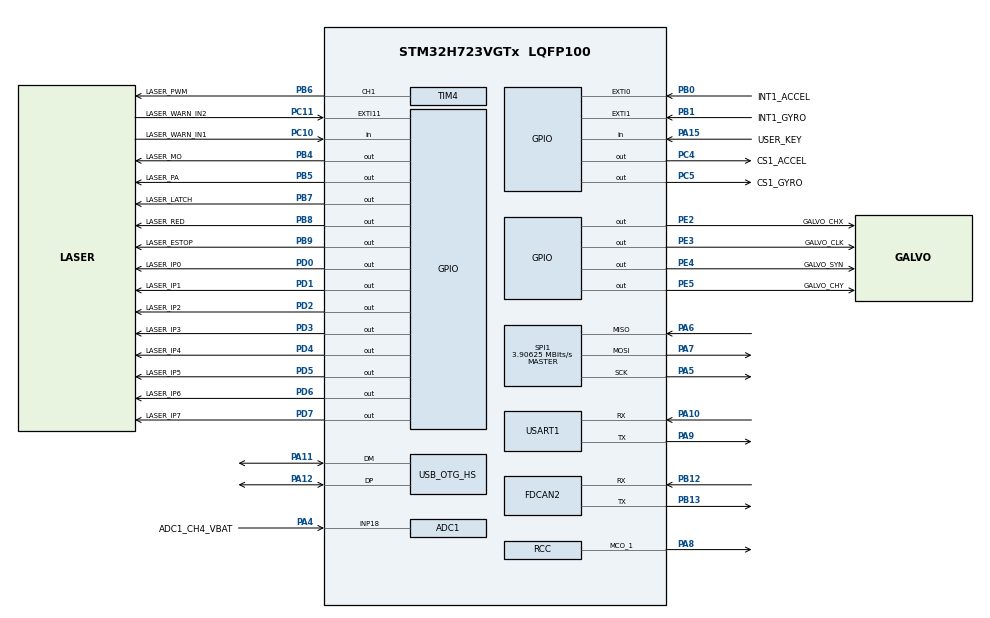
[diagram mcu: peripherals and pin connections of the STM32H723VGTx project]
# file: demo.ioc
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ADC1.Channel-0\#ChannelRegularConversion=ADC_CHANNEL_18
ADC1.ClockPrescaler=ADC_CLOCK_ASYNC_DIV64
ADC1.NbrOfConversionFlag=1
ADC1.OffsetNumber-0\#ChannelRegularConversion=ADC_OFFSET_NONE
ADC1.OffsetSignedSaturation-0\#ChannelRegularConversion=DISABLE
ADC1.Rank-0\#ChannelRegularConversion=1
ADC1.SamplingTime-0\#ChannelRegularConversion=ADC_SAMPLETIME_1CYCLE_5
ADC1.master=1
CORTEX_M7.AccessPermission_Spec=MPU_REGION_FULL_ACCESS
CORTEX_M7.BaseAddress_Spec=0x30000000
CORTEX_M7.CPU_DCache=Enabled
CORTEX_M7.CPU_ICache=Enabled
CORTEX_M7.Enable_S-Cortex_Memory_Protection_Unit_Region1_Settings_S=__NULL
CORTEX_M7.IsShareable_Spec=MPU_ACCESS_NOT_SHAREABLE
CORTEX_M7.MPU_Control=MPU_PRIVILEGED_DEFAULT
CORTEX_M7.Size_Spec=MPU_REGION_SIZE_16KB
CORTEX_M7.SubRegionDisable_Spec=0x0
CORTEX_M7.TypeExtField_Spec=MPU_TEX_LEVEL1
CORTEX_M7.default_mode_Activation=1
Dma.Request0=SPI1_RX
Dma.Request1=SPI1_TX
Dma.Request2=USART1_RX
Dma.Request3=USART1_TX
Dma.Request4=TIM7_UP
Dma.SPI1_RX.0.Direction=DMA_PERIPH_TO_MEMORY
Dma.SPI1_RX.0.EventEnable=DISABLE
Dma.SPI1_RX.0.FIFOMode=DMA_FIFOMODE_DISABLE
Dma.SPI1_RX.0.Instance=DMA1_Stream0
Dma.SPI1_RX.0.MemDataAlignment=DMA_MDATAALIGN_BYTE
Dma.SPI1_RX.0.MemInc=DMA_MINC_ENABLE
Dma.SPI1_RX.0.Mode=DMA_NORMAL
Dma.SPI1_RX.0.PeriphDataAlignment=DMA_PDATAALIGN_BYTE
Dma.SPI1_RX.0.PeriphInc=DMA_PINC_DISABLE
Dma.SPI1_RX.0.Polarity=HAL_DMAMUX_REQ_GEN_RISING
Dma.SPI1_RX.0.Priority=DMA_PRIORITY_VERY_HIGH
Dma.SPI1_RX.0.RequestNumber=1
Dma.SPI1_RX.0.SignalID=NONE
Dma.SPI1_RX.0.SyncEnable=DISABLE
Dma.SPI1_RX.0.SyncPolarity=HAL_DMAMUX_SYNC_NO_EVENT
Dma.SPI1_RX.0.SyncRequestNumber=1
Dma.SPI1_RX.0.SyncSignalID=NONE
Dma.SPI1_TX.1.Direction=DMA_MEMORY_TO_PERIPH
Dma.SPI1_TX.1.EventEnable=DISABLE
Dma.SPI1_TX.1.FIFOMode=DMA_FIFOMODE_DISABLE
Dma.SPI1_TX.1.Instance=DMA1_Stream1
Dma.SPI1_TX.1.MemDataAlignment=DMA_MDATAALIGN_BYTE
Dma.SPI1_TX.1.MemInc=DMA_MINC_ENABLE
Dma.SPI1_TX.1.Mode=DMA_NORMAL
Dma.SPI1_TX.1.PeriphDataAlignment=DMA_PDATAALIGN_BYTE
Dma.SPI1_TX.1.PeriphInc=DMA_PINC_DISABLE
Dma.SPI1_TX.1.Polarity=HAL_DMAMUX_REQ_GEN_RISING
Dma.SPI1_TX.1.Priority=DMA_PRIORITY_VERY_HIGH
Dma.SPI1_TX.1.RequestNumber=1
Dma.SPI1_TX.1.SignalID=NONE
Dma.SPI1_TX.1.SyncEnable=DISABLE
Dma.SPI1_TX.1.SyncPolarity=HAL_DMAMUX_SYNC_NO_EVENT
Dma.SPI1_TX.1.SyncRequestNumber=1
Dma.SPI1_TX.1.SyncSignalID=NONE
Dma.TIM7_UP.4.Direction=DMA_MEMORY_TO_PERIPH
Dma.TIM7_UP.4.EventEnable=DISABLE
Dma.TIM7_UP.4.FIFOMode=DMA_FIFOMODE_DISABLE
Dma.TIM7_UP.4.Instance=DMA1_Stream4
Dma.TIM7_UP.4.MemDataAlignment=DMA_MDATAALIGN_WORD
Dma.TIM7_UP.4.MemInc=DMA_MINC_ENABLE
Dma.TIM7_UP.4.Mode=DMA_NORMAL
Dma.TIM7_UP.4.PeriphDataAlignment=DMA_PDATAALIGN_WORD
Dma.TIM7_UP.4.PeriphInc=DMA_PINC_DISABLE
Dma.TIM7_UP.4.Polarity=HAL_DMAMUX_REQ_GEN_RISING
Dma.TIM7_UP.4.Priority=DMA_PRIORITY_VERY_HIGH
Dma.TIM7_UP.4.RequestNumber=1
Dma.TIM7_UP.4.SignalID=NONE
Dma.TIM7_UP.4.SyncEnable=DISABLE
Dma.TIM7_UP.4.SyncPolarity=HAL_DMAMUX_SYNC_NO_EVENT
Dma.TIM7_UP.4.SyncRequestNumber=1
Dma.TIM7_UP.4.SyncSignalID=NONE
Dma.USART1_RX.2.Direction=DMA_PERIPH_TO_MEMORY
Dma.USART1_RX.2.EventEnable=DISABLE
Dma.USART1_RX.2.FIFOMode=DMA_FIFOMODE_DISABLE
Dma.USART1_RX.2.Instance=DMA1_Stream2
Dma.USART1_RX.2.MemDataAlignment=DMA_MDATAALIGN_BYTE
Dma.USART1_RX.2.MemInc=DMA_MINC_ENABLE
Dma.USART1_RX.2.Mode=DMA_NORMAL
Dma.USART1_RX.2.PeriphDataAlignment=DMA_PDATAALIGN_BYTE
Dma.USART1_RX.2.PeriphInc=DMA_PINC_DISABLE
Dma.USART1_RX.2.Polarity=HAL_DMAMUX_REQ_GEN_RISING
Dma.USART1_RX.2.Priority=DMA_PRIORITY_LOW
Dma.USART1_RX.2.RequestNumber=1
Dma.USART1_RX.2.SignalID=NONE
Dma.USART1_RX.2.SyncEnable=DISABLE
Dma.USART1_RX.2.SyncPolarity=HAL_DMAMUX_SYNC_NO_EVENT
Dma.USART1_RX.2.SyncRequestNumber=1
Dma.USART1_RX.2.SyncSignalID=NONE
Dma.USART1_TX.3.Direction=DMA_MEMORY_TO_PERIPH
Dma.USART1_TX.3.EventEnable=DISABLE
Dma.USART1_TX.3.FIFOMode=DMA_FIFOMODE_DISABLE
Dma.USART1_TX.3.Instance=DMA1_Stream3
Dma.USART1_TX.3.MemDataAlignment=DMA_MDATAALIGN_BYTE
Dma.USART1_TX.3.MemInc=DMA_MINC_ENABLE
Dma.USART1_TX.3.Mode=DMA_NORMAL
Dma.USART1_TX.3.PeriphDataAlignment=DMA_PDATAALIGN_BYTE
Dma.USART1_TX.3.PeriphInc=DMA_PINC_DISABLE
Dma.USART1_TX.3.Polarity=HAL_DMAMUX_REQ_GEN_RISING
Dma.USART1_TX.3.Priority=DMA_PRIORITY_LOW
Dma.USART1_TX.3.RequestNumber=1
Dma.USART1_TX.3.SignalID=NONE
Dma.USART1_TX.3.SyncEnable=DISABLE
Dma.USART1_TX.3.SyncPolarity=HAL_DMAMUX_SYNC_NO_EVENT
Dma.USART1_TX.3.SyncRequestNumber=1
Dma.USART1_TX.3.SyncSignalID=NONE
FDCAN2.AutoRetransmission=ENABLE
FDCAN2.CalculateBaudRateNominal=1000000
FDCAN2.CalculateTimeBitNominal=1000
FDCAN2.CalculateTimeQuantumNominal=40.0
FDCAN2.DataPrescaler=3
FDCAN2.DataSyncJumpWidth=10
FDCAN2.DataTimeSeg1=29
FDCAN2.DataTimeSeg2=10
FDCAN2.NominalPrescaler=5
FDCAN2.NominalTimeSeg1=19
FDCAN2.NominalTimeSeg2=5
FDCAN2.RxFifo0ElmtsNbr=4
FDCAN2.RxFifo1ElmtsNbr=4
FDCAN2.StdFiltersNbr=14
FDCAN2.TxFifoQueueElmtsNbr=32
FREERTOS.Tasks01=defaultTask,24,3584,StartDefaultTask,Default,NULL,Dynamic,NULL,NULL
FREERTOS.configENABLE_FPU=1
FREERTOS.configTOTAL_HEAP_SIZE=25600
FREERTOS.configUSE_TIMERS=1
Mcu.Family=STM32H7
Mcu.Name=STM32H723VGTx
Mcu.Package=LQFP100
NVIC.DMA1_Stream0_IRQn=true\:5\:0\:false\:false\:true\:true\:false\:true\:true
NVIC.DMA1_Stream1_IRQn=true\:5\:0\:false\:false\:true\:true\:false\:true\:true
NVIC.DMA1_Stream2_IRQn=true\:5\:0\:false\:false\:true\:true\:false\:true\:true
NVIC.DMA1_Stream3_IRQn=true\:5\:0\:false\:false\:true\:true\:false\:true\:true
NVIC.DMA1_Stream4_IRQn=true\:5\:0\:false\:false\:true\:true\:false\:true\:true
NVIC.FDCAN2_IT0_IRQn=true\:5\:0\:false\:false\:true\:true\:true\:true\:true
NVIC.FDCAN2_IT1_IRQn=true\:5\:0\:false\:false\:true\:true\:true\:true\:true
NVIC.OTG_HS_IRQn=true\:5\:0\:false\:false\:true\:true\:true\:true\:true
NVIC.PriorityGroup=NVIC_PRIORITYGROUP_4
NVIC.SPI1_IRQn=true\:5\:0\:false\:false\:true\:true\:false\:true\:true
NVIC.TIM6_DAC_IRQn=true\:15\:0\:false\:false\:true\:false\:false\:true\:true
NVIC.TimeBase=TIM6_DAC_IRQn
NVIC.TimeBaseIP=TIM6
NVIC.USART1_IRQn=true\:5\:0\:false\:false\:true\:true\:true\:true\:true
PA10.Mode=Asynchronous
PA10.Signal=USART1_RX
PA11.Mode=Device_Only_FS
PA11.Signal=USB_OTG_HS_DM
PA12.Mode=Device_Only_FS
PA12.Signal=USB_OTG_HS_DP
PA13(JTMS/SWDIO).Mode=Serial_Wire
PA13(JTMS/SWDIO).Signal=DEBUG_JTMS-SWDIO
PA14(JTCK/SWCLK).Mode=Serial_Wire
PA14(JTCK/SWCLK).Signal=DEBUG_JTCK-SWCLK
PA15(JTDI).GPIO_Label=USER_KEY
PA15(JTDI).Signal=GPIO_Input
PA4.GPIO_Label=ADC1_CH4_VBAT
PA4.Signal=ADCx_INP18
PA5.GPIO_Speed=GPIO_SPEED_FREQ_VERY_HIGH
PA5.Mode=Full_Duplex_Master
PA5.Signal=SPI1_SCK
PA6.GPIO_Speed=GPIO_SPEED_FREQ_VERY_HIGH
PA6.Mode=Full_Duplex_Master
PA6.Signal=SPI1_MISO
PA7.GPIO_Speed=GPIO_SPEED_FREQ_VERY_HIGH
PA7.Mode=Full_Duplex_Master
PA7.Signal=SPI1_MOSI
PA8.Mode=Clock-out-1
PA8.Signal=RCC_MCO_1
PA9.Mode=Asynchronous
PA9.Signal=USART1_TX
PB0.GPIO_Label=INT1_ACCEL
PB0.Signal=GPXTI0
PB1.GPIO_Label=INT1_GYRO
PB1.Signal=GPXTI1
PB12.Mode=FDCAN_Activate
PB12.Signal=FDCAN2_RX
PB13.Mode=FDCAN_Activate
PB13.Signal=FDCAN2_TX
PB4(NJTRST).GPIO_Label=LASER_MO
PB4(NJTRST).GPIO_Speed=GPIO_SPEED_FREQ_VERY_HIGH
PB4(NJTRST).PinState=GPIO_PIN_RESET
PB4(NJTRST).Signal=GPIO_Output
PB5.GPIO_Label=LASER_PA
PB5.GPIO_Speed=GPIO_SPEED_FREQ_VERY_HIGH
PB5.PinState=GPIO_PIN_RESET
PB5.Signal=GPIO_Output
PB6.GPIO_Label=LASER_PWM
PB6.Signal=S_TIM4_CH1
PB7.GPIO_Label=LASER_LATCH
PB7.GPIO_Speed=GPIO_SPEED_FREQ_VERY_HIGH
PB7.PinState=GPIO_PIN_RESET
PB7.Signal=GPIO_Output
PB8.GPIO_Label=LASER_RED
PB8.GPIO_Speed=GPIO_SPEED_FREQ_VERY_HIGH
PB8.PinState=GPIO_PIN_RESET
PB8.Signal=GPIO_Output
PB9.GPIO_Label=LASER_ESTOP
PB9.GPIO_Speed=GPIO_SPEED_FREQ_VERY_HIGH
PB9.PinState=GPIO_PIN_RESET
PB9.Signal=GPIO_Output
PC10.GPIO_Label=LASER_WARN_IN1
PC10.GPIO_PuPd=GPIO_PULLUP
PC10.Signal=GPIO_Input
PC11.GPIO_Label=LASER_WARN_IN2
PC11.GPIO_PuPd=GPIO_PULLUP
PC11.Signal=GPXTI11
PC4.GPIO_Label=CS1_ACCEL
PC4.GPIO_Speed=GPIO_SPEED_FREQ_VERY_HIGH
PC4.PinState=GPIO_PIN_SET
PC4.Signal=GPIO_Output
PC5.GPIO_Label=CS1_GYRO
PC5.GPIO_Speed=GPIO_SPEED_FREQ_VERY_HIGH
PC5.PinState=GPIO_PIN_SET
PC5.Signal=GPIO_Output
PD0.GPIO_Label=LASER_IP0
PD0.GPIO_Speed=GPIO_SPEED_FREQ_VERY_HIGH
PD0.PinState=GPIO_PIN_RESET
PD0.Signal=GPIO_Output
PD1.GPIO_Label=LASER_IP1
PD1.GPIO_Speed=GPIO_SPEED_FREQ_VERY_HIGH
PD1.PinState=GPIO_PIN_RESET
PD1.Signal=GPIO_Output
PD2.GPIO_Label=LASER_IP2
PD2.GPIO_Speed=GPIO_SPEED_FREQ_VERY_HIGH
PD2.PinState=GPIO_PIN_RESET
PD2.Signal=GPIO_Output
PD3.GPIO_Label=LASER_IP3
PD3.GPIO_Speed=GPIO_SPEED_FREQ_VERY_HIGH
PD3.PinState=GPIO_PIN_RESET
PD3.Signal=GPIO_Output
PD4.GPIO_Label=LASER_IP4
PD4.GPIO_Speed=GPIO_SPEED_FREQ_VERY_HIGH
PD4.PinState=GPIO_PIN_RESET
PD4.Signal=GPIO_Output
PD5.GPIO_Label=LASER_IP5
PD5.GPIO_Speed=GPIO_SPEED_FREQ_VERY_HIGH
PD5.PinState=GPIO_PIN_RESET
PD5.Signal=GPIO_Output
PD6.GPIO_Label=LASER_IP6
PD6.GPIO_Speed=GPIO_SPEED_FREQ_VERY_HIGH
PD6.PinState=GPIO_PIN_RESET
PD6.Signal=GPIO_Output
PD7.GPIO_Label=LASER_IP7
PD7.GPIO_Speed=GPIO_SPEED_FREQ_VERY_HIGH
PD7.PinState=GPIO_PIN_RESET
PD7.Signal=GPIO_Output
PE2.GPIO_Label=GALVO_CHX
PE2.GPIO_Speed=GPIO_SPEED_FREQ_VERY_HIGH
PE2.Signal=GPIO_Output
PE3.GPIO_Label=GALVO_CLK
PE3.GPIO_Speed=GPIO_SPEED_FREQ_VERY_HIGH
PE3.Signal=GPIO_Output
PE4.GPIO_Label=GALVO_SYN
PE4.GPIO_Speed=GPIO_SPEED_FREQ_VERY_HIGH
PE4.Signal=GPIO_Output
PE5.GPIO_Label=GALVO_CHY
PE5.GPIO_Speed=GPIO_SPEED_FREQ_VERY_HIGH
PE5.Signal=GPIO_Output
PH0-OSC_IN.Mode=HSE-External-Oscillator
PH0-OSC_IN.Signal=RCC_OSC_IN
PH1-OSC_OUT.Mode=HSE-External-Oscillator
PH1-OSC_OUT.Signal=RCC_OSC_OUT
ProjectManager.HeapSize=0x1000
ProjectManager.StackSize=0x1000
ProjectManager.TargetToolchain=Makefile
RCC.ADCFreq_Value=100000000
RCC.APB1Freq_Value=125000000
RCC.APB2Freq_Value=125000000
RCC.APB3Freq_Value=125000000
RCC.APB4Freq_Value=125000000
RCC.CortexFreq_Value=500000000
RCC.D1PPRE=RCC_APB3_DIV2
RCC.D2PPRE1=RCC_APB1_DIV2
RCC.D2PPRE2=RCC_APB2_DIV2
RCC.D3PPRE=RCC_APB4_DIV2
RCC.DIVM1=2
RCC.DIVM2=2
RCC.DIVM3=5
RCC.DIVN1=40
RCC.DIVN2=16
RCC.DIVN3=96
RCC.DIVP1=1
RCC.DIVP3=10
RCC.DIVQ1=4
RCC.HCLKFreq_Value=250000000
RCC.HPRE=RCC_HCLK_DIV2
RCC.PLL2FRACN=0
RCC.PLL3FRACN=0
RCC.PLLFRACN=0
RCC.PLLSourceVirtual=RCC_PLLSOURCE_HSE
RCC.SYSCLKFreq_VALUE=500000000
RCC.SYSCLKSource=RCC_SYSCLKSOURCE_PLLCLK
RCC.USBCLockSelection=RCC_USBCLKSOURCE_HSI48
RCC.USBFreq_Value=48000000
SH.ADCx_INP18.0=ADC1_INP18,IN18-Single-Ended
SH.S_TIM4_CH1.0=TIM4_CH1,PWM Generation1 CH1
SPI1.BaudRatePrescaler=SPI_BAUDRATEPRESCALER_32
SPI1.CLKPhase=SPI_PHASE_2EDGE
SPI1.CLKPolarity=SPI_POLARITY_HIGH
SPI1.CalculateBaudRate=3.90625 MBits/s
SPI1.DataSize=SPI_DATASIZE_8BIT
SPI1.Direction=SPI_DIRECTION_2LINES
SPI1.Mode=SPI_MODE_MASTER
SPI1.VirtualType=VM_MASTER
TIM4.Channel-PWM\ Generation1\ CH1=TIM_CHANNEL_1
TIM7.AutoReloadPreload=TIM_AUTORELOAD_PRELOAD_ENABLE
TIM7.Period=61
TIM7.TIM_MasterOutputTrigger=TIM_TRGO_UPDATE
USART1.VirtualMode-Asynchronous=VM_ASYNC
USB_DEVICE.CLASS_NAME_HS=CDC
USB_DEVICE.VirtualMode=Cdc
USB_DEVICE.VirtualModeHS=Cdc_HS
USB_OTG_HS.VirtualMode-Device_Only_FS=Device_Only_FS
VP_FREERTOS_VS_CMSIS_V2.Mode=CMSIS_V2
VP_MEMORYMAP_VS_MEMORYMAP.Mode=CurAppReg
VP_RCC_USB.Mode=USB_HS
VP_SYS_VS_tim6.Mode=TIM6
VP_TIM4_VS_ClockSourceINT.Mode=Internal
VP_TIM4_VS_OPM.Mode=OPM_bit
VP_TIM7_VS_ClockSourceINT.Mode=Enable_Timer
VP_USB_DEVICE_VS_USB_DEVICE_CDC_HS.Mode=CDC_HS
board=custom

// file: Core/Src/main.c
/* USER CODE BEGIN Header */
/**
  ******************************************************************************
  * @file           : main.c
  * @brief          : Main program body
  ******************************************************************************
  * @attention
  *
  * Copyright (c) 2026 STMicroelectronics.
  * All rights reserved.
  *
  * This software is licensed under terms that can be found in the LICENSE file
  * in the root directory of this software component.
  * If no LICENSE file comes with this software, it is provided AS-IS.
  *
  ******************************************************************************
  */
/* USER CODE END Header */
#include "main.h"
#include "cmsis_os.h"
#include "adc.h"
#include "dma.h"
#include "fdcan.h"
#include "spi.h"
#include "tim.h"
#include "usart.h"
#include "usb_device.h"
#include "gpio.h"

/* USER CODE BEGIN Includes */
#include "robot.h"
#include "bsp_log.h"
/* USER CODE END Includes */

void SystemClock_Config(void);
static void MPU_Config(void);
void MX_FREERTOS_Init(void);

int main(void)
{

  /* MPU Configuration--------------------------------------------------------*/
  MPU_Config();

  /* Enable the CPU Cache */

  /* Enable I-Cache---------------------------------------------------------*/
  SCB_EnableICache();

  /* Enable D-Cache---------------------------------------------------------*/
  SCB_EnableDCache();

  /* MCU Configuration--------------------------------------------------------*/

  /* Reset of all peripherals, Initializes the Flash interface and the Systick. */
  HAL_Init();

  /* Configure the system clock */
  SystemClock_Config();

  /* Initialize all configured peripherals */
  MX_GPIO_Init();
  MX_DMA_Init();
  MX_SPI1_Init();
  MX_USART1_UART_Init();
  MX_FDCAN2_Init();
  MX_TIM4_Init();
  MX_TIM7_Init();
  MX_ADC1_Init();
  /* USER CODE BEGIN 2 */
  RobotInit(); // 唯一的初始化入口（你的云台和激光逻辑都在这里面）
  LOGINFO("[main] SystemInit() and RobotInit() done");
  /* USER CODE END 2 */

  /* Init scheduler */
  osKernelInitialize();  /* Call init function for freertos objects (in cmsis_os2.c) */
  MX_FREERTOS_Init();

  /* Start scheduler */
  osKernelStart();

  /* We should never get here as control is now taken by the scheduler */

  /* Infinite loop */
  while (1)
  {

  }
}

void SystemClock_Config(void)
{
  RCC_OscInitTypeDef RCC_OscInitStruct = {0};
  RCC_ClkInitTypeDef RCC_ClkInitStruct = {0};
  RCC_CRSInitTypeDef RCC_CRSInitStruct = {0};

  /** Supply configuration update enable
  */
  HAL_PWREx_ConfigSupply(PWR_LDO_SUPPLY);

  /** Configure the main internal regulator output voltage
  */
  __HAL_PWR_VOLTAGESCALING_CONFIG(PWR_REGULATOR_VOLTAGE_SCALE0);

  while(!__HAL_PWR_GET_FLAG(PWR_FLAG_VOSRDY)) {}

  /** Initializes the RCC Oscillators according to the specified parameters
  * in the RCC_OscInitTypeDef structure.
  */
  RCC_OscInitStruct.OscillatorType = RCC_OSCILLATORTYPE_HSI48|RCC_OSCILLATORTYPE_HSI
                              |RCC_OSCILLATORTYPE_HSE;
  RCC_OscInitStruct.HSEState = RCC_HSE_ON;
  RCC_OscInitStruct.HSIState = RCC_HSI_DIV1;
  RCC_OscInitStruct.HSICalibrationValue = 64;
  RCC_OscInitStruct.HSI48State = RCC_HSI48_ON;
  RCC_OscInitStruct.PLL.PLLState = RCC_PLL_ON;
  RCC_OscInitStruct.PLL.PLLSource = RCC_PLLSOURCE_HSE;
  RCC_OscInitStruct.PLL.PLLM = 2;
  RCC_OscInitStruct.PLL.PLLN = 40;
  RCC_OscInitStruct.PLL.PLLP = 1;
  RCC_OscInitStruct.PLL.PLLQ = 4;
  RCC_OscInitStruct.PLL.PLLR = 2;
  RCC_OscInitStruct.PLL.PLLRGE = RCC_PLL1VCIRANGE_3;
  RCC_OscInitStruct.PLL.PLLVCOSEL = RCC_PLL1VCOWIDE;
  RCC_OscInitStruct.PLL.PLLFRACN = 0;
  if (HAL_RCC_OscConfig(&RCC_OscInitStruct) != HAL_OK)
  {
    Error_Handler();
  }

  /** Initializes the CPU, AHB and APB buses clocks
  */
  RCC_ClkInitStruct.ClockType = RCC_CLOCKTYPE_HCLK|RCC_CLOCKTYPE_SYSCLK
                              |RCC_CLOCKTYPE_PCLK1|RCC_CLOCKTYPE_PCLK2
                              |RCC_CLOCKTYPE_D3PCLK1|RCC_CLOCKTYPE_D1PCLK1;
  RCC_ClkInitStruct.SYSCLKSource = RCC_SYSCLKSOURCE_PLLCLK;
  RCC_ClkInitStruct.SYSCLKDivider = RCC_SYSCLK_DIV1;
  RCC_ClkInitStruct.AHBCLKDivider = RCC_HCLK_DIV2;
  RCC_ClkInitStruct.APB3CLKDivider = RCC_APB3_DIV2;
  RCC_ClkInitStruct.APB1CLKDivider = RCC_APB1_DIV2;
  RCC_ClkInitStruct.APB2CLKDivider = RCC_APB2_DIV2;
  RCC_ClkInitStruct.APB4CLKDivider = RCC_APB4_DIV2;

  if (HAL_RCC_ClockConfig(&RCC_ClkInitStruct, FLASH_LATENCY_3) != HAL_OK)
  {
    Error_Handler();
  }
  HAL_RCC_MCOConfig(RCC_MCO1, RCC_MCO1SOURCE_HSI, RCC_MCODIV_1);

  /** Enable the SYSCFG APB clock
  */
  __HAL_RCC_CRS_CLK_ENABLE();

  /** Configures CRS
  */
  RCC_CRSInitStruct.Prescaler = RCC_CRS_SYNC_DIV1;
  RCC_CRSInitStruct.Source = RCC_CRS_SYNC_SOURCE_USB2;
  RCC_CRSInitStruct.Polarity = RCC_CRS_SYNC_POLARITY_RISING;
  RCC_CRSInitStruct.ReloadValue = __HAL_RCC_CRS_RELOADVALUE_CALCULATE(48000000,1000);
  RCC_CRSInitStruct.ErrorLimitValue = 34;
  RCC_CRSInitStruct.HSI48CalibrationValue = 32;

  HAL_RCCEx_CRSConfig(&RCC_CRSInitStruct);
}

 /* MPU Configuration */

void MPU_Config(void)
{
  MPU_Region_InitTypeDef MPU_InitStruct = {0};

  /* Disables the MPU */
  HAL_MPU_Disable();

  /** Initializes and configures the Region and the memory to be protected
  */
  MPU_InitStruct.Enable = MPU_REGION_ENABLE;
  MPU_InitStruct.Number = MPU_REGION_NUMBER0;
  MPU_InitStruct.BaseAddress = 0x30000000;
  MPU_InitStruct.Size = MPU_REGION_SIZE_16KB;
  MPU_InitStruct.SubRegionDisable = 0x0;
  MPU_InitStruct.TypeExtField = MPU_TEX_LEVEL1;
  MPU_InitStruct.AccessPermission = MPU_REGION_FULL_ACCESS;
  MPU_InitStruct.DisableExec = MPU_INSTRUCTION_ACCESS_DISABLE;
  MPU_InitStruct.IsShareable = MPU_ACCESS_NOT_SHAREABLE;
  MPU_InitStruct.IsCacheable = MPU_ACCESS_NOT_CACHEABLE;
  MPU_InitStruct.IsBufferable = MPU_ACCESS_NOT_BUFFERABLE;

  HAL_MPU_ConfigRegion(&MPU_InitStruct);
  /* Enables the MPU */
  HAL_MPU_Enable(MPU_PRIVILEGED_DEFAULT);

}

void HAL_TIM_PeriodElapsedCallback(TIM_HandleTypeDef *htim)
{
  if (htim->Instance == TIM6)
  {
    HAL_IncTick();
  }
}

void Error_Handler(void)
{
  __disable_irq();
  while (1)
  {
  }
}

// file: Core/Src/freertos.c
/* USER CODE BEGIN Header */
/**
  ******************************************************************************
  * File Name          : freertos.c
  * Description        : Code for freertos applications
  ******************************************************************************
  * @attention
  *
  * Copyright (c) 2026 STMicroelectronics.
  * All rights reserved.
  *
  * This software is licensed under terms that can be found in the LICENSE file
  * in the root directory of this software component.
  * If no LICENSE file comes with this software, it is provided AS-IS.
  *
  ******************************************************************************
  */
/* USER CODE END Header */

#include "FreeRTOS.h"
#include "task.h"
#include "main.h"
#include "cmsis_os.h"

/* Definitions for defaultTask */
osThreadId_t defaultTaskHandle;
const osThreadAttr_t defaultTask_attributes = {
  .name = "defaultTask",
  .stack_size = 3584 * 4,//14KB
  .priority = (osPriority_t) osPriorityNormal,
};

void StartDefaultTask(void *argument);

extern void MX_USB_DEVICE_Init(void);
void MX_FREERTOS_Init(void); /* (MISRA C 2004 rule 8.1) */

void MX_FREERTOS_Init(void) {

  /* Create the thread(s) */
  /* creation of defaultTask */
  defaultTaskHandle = osThreadNew(StartDefaultTask, NULL, &defaultTask_attributes);

}

void StartDefaultTask(void *argument)
{
  /* init code for USB_DEVICE */
  MX_USB_DEVICE_Init();
  for(;;)
  {
    osDelay(1);
  }
}
